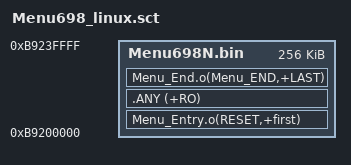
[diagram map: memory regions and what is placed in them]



LOAD_Menu 0xB9200000 0x00040000;//256K
{
  Menu698N.bin 0xB9200000 0x00040000;//256K
  {
;//Entry
		Menu_Entry.o(RESET,+first)
		;//*(InRoot$$Sections);//__main()的一部分
    .ANY (+RO)
		
;//End
		Menu_End.o(Menu_END,+LAST)
  }
	
	;RW_RAM1 0x00400000 0x00040000;//+0;RW_RAM1 start address is after ER_ROM1
	;{
		;.ANY (+RW +ZI)
	;}
	;//ARM_LIB_HEAP  0x00100000 EMPTY  0x00080000   {}
	;//ARM_LIB_STACK 0x00180000 EMPTY -0x00080000   {}
}



